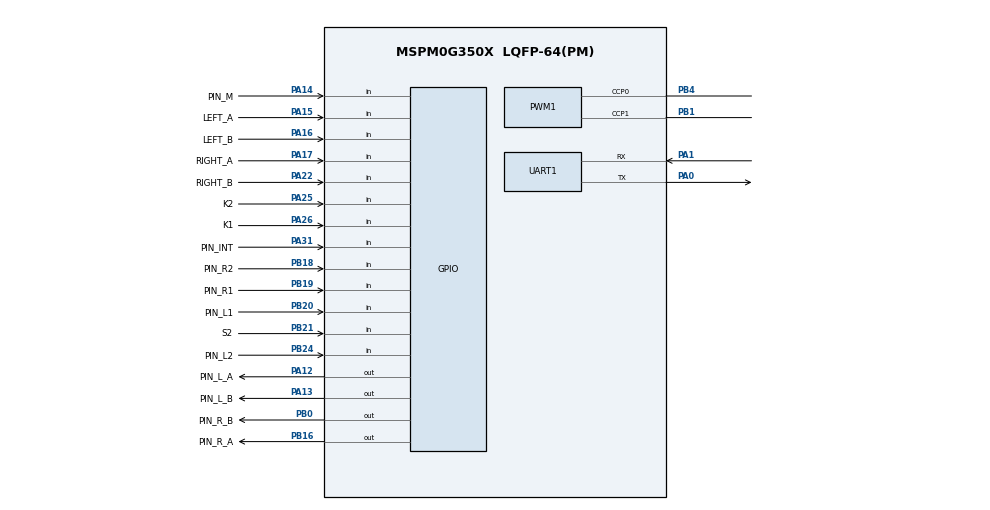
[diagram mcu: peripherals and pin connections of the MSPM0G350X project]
/**
 * @cliArgs --device "MSPM0G350X" --part "Default" --package "LQFP-64(PM)" --product "mspm0_sdk@2.05.01.00"
 * @versions {"tool":"1.24.0+4110"}
 */

/**
 * Import the modules used in this configuration.
 */
const GPIO   = scripting.addModule("/ti/driverlib/GPIO", {}, false);
const GPIO1  = GPIO.addInstance();
const GPIO2  = GPIO.addInstance();
const GPIO3  = GPIO.addInstance();
const GPIO4  = GPIO.addInstance();
const GPIO5  = GPIO.addInstance();
const GPIO6  = GPIO.addInstance();
const PWM    = scripting.addModule("/ti/driverlib/PWM", {}, false);
const PWM1   = PWM.addInstance();
const SYSCTL = scripting.addModule("/ti/driverlib/SYSCTL");
const TIMER  = scripting.addModule("/ti/driverlib/TIMER", {}, false);
const TIMER1 = TIMER.addInstance();
const UART   = scripting.addModule("/ti/driverlib/UART", {}, false);
const UART1  = UART.addInstance();

/**
 * Write custom configuration values to the imported modules.
 */
const divider7       = system.clockTree["PLL_PDIV"];
divider7.divideValue = 2;

const divider9       = system.clockTree["UDIV"];
divider9.divideValue = 2;

const multiplier2         = system.clockTree["PLL_QDIV"];
multiplier2.multiplyValue = 5;

const mux8       = system.clockTree["HSCLKMUX"];
mux8.inputSelect = "HSCLKMUX_SYSPLL2X";

GPIO1.$name                              = "GPIO_MPU6050";
GPIO1.associatedPins[0].$name            = "PIN_INT";
GPIO1.associatedPins[0].direction        = "INPUT";
GPIO1.associatedPins[0].internalResistor = "PULL_UP";
GPIO1.associatedPins[0].interruptEn      = true;
GPIO1.associatedPins[0].polarity         = "FALL";
GPIO1.associatedPins[0].pin.$assign      = "PA31";

const Board = scripting.addModule("/ti/driverlib/Board", {}, false);

GPIO2.$name                         = "GPIO_R";
GPIO2.associatedPins.create(2);
GPIO2.associatedPins[0].$name       = "PIN_R_A";
GPIO2.associatedPins[0].pin.$assign = "PB16";
GPIO2.associatedPins[1].$name       = "PIN_R_B";
GPIO2.associatedPins[1].pin.$assign = "PB0";

GPIO3.$name                         = "GPIO_L";
GPIO3.associatedPins.create(2);
GPIO3.associatedPins[0].$name       = "PIN_L_B";
GPIO3.associatedPins[0].pin.$assign = "PA13";
GPIO3.associatedPins[1].$name       = "PIN_L_A";
GPIO3.associatedPins[1].pin.$assign = "PA12";

GPIO4.$name                         = "GPIO_ECONDER";
GPIO4.associatedPins.create(4);
GPIO4.associatedPins[0].$name       = "LEFT_A";
GPIO4.associatedPins[0].direction   = "INPUT";
GPIO4.associatedPins[0].interruptEn = true;
GPIO4.associatedPins[0].polarity    = "RISE";
GPIO4.associatedPins[0].pin.$assign = "PA15";
GPIO4.associatedPins[1].$name       = "LEFT_B";
GPIO4.associatedPins[1].direction   = "INPUT";
GPIO4.associatedPins[1].pin.$assign = "PA16";
GPIO4.associatedPins[2].direction   = "INPUT";
GPIO4.associatedPins[2].$name       = "RIGHT_A";
GPIO4.associatedPins[2].interruptEn = true;
GPIO4.associatedPins[2].polarity    = "RISE";
GPIO4.associatedPins[2].pin.$assign = "PA17";
GPIO4.associatedPins[3].direction   = "INPUT";
GPIO4.associatedPins[3].$name       = "RIGHT_B";
GPIO4.associatedPins[3].polarity    = "RISE";
GPIO4.associatedPins[3].pin.$assign = "PA22";

GPIO5.$name                         = "GPIO_HUIDU";
GPIO5.associatedPins.create(5);
GPIO5.associatedPins[0].$name       = "PIN_L2";
GPIO5.associatedPins[0].direction   = "INPUT";
GPIO5.associatedPins[0].pin.$assign = "PB24";
GPIO5.associatedPins[1].$name       = "PIN_L1";
GPIO5.associatedPins[1].direction   = "INPUT";
GPIO5.associatedPins[1].pin.$assign = "PB20";
GPIO5.associatedPins[2].$name       = "PIN_M";
GPIO5.associatedPins[2].direction   = "INPUT";
GPIO5.associatedPins[2].pin.$assign = "PA14";
GPIO5.associatedPins[3].$name       = "PIN_R2";
GPIO5.associatedPins[3].direction   = "INPUT";
GPIO5.associatedPins[3].pin.$assign = "PB18";
GPIO5.associatedPins[4].$name       = "PIN_R1";
GPIO5.associatedPins[4].direction   = "INPUT";
GPIO5.associatedPins[4].pin.$assign = "PB19";

GPIO6.$name                              = "KEY";
GPIO6.associatedPins.create(3);
GPIO6.associatedPins[0].$name            = "S2";
GPIO6.associatedPins[0].direction        = "INPUT";
GPIO6.associatedPins[0].pin.$assign      = "PB21";
GPIO6.associatedPins[1].direction        = "INPUT";
GPIO6.associatedPins[1].$name            = "K1";
GPIO6.associatedPins[1].internalResistor = "PULL_UP";
GPIO6.associatedPins[1].pin.$assign      = "PA26";
GPIO6.associatedPins[2].$name            = "K2";
GPIO6.associatedPins[2].direction        = "INPUT";
GPIO6.associatedPins[2].internalResistor = "PULL_UP";
GPIO6.associatedPins[2].pin.$assign      = "PA25";

PWM1.$name                              = "PWM";
PWM1.pwmMode                            = "EDGE_ALIGN_UP";
PWM1.timerCount                         = 200;
PWM1.peripheral.$assign                 = "TIMA1";
PWM1.peripheral.ccp0Pin.$assign         = "PB4";
PWM1.peripheral.ccp1Pin.$assign         = "PB1";
PWM1.PWM_CHANNEL_0.$name                = "ti_driverlib_pwm_PWMTimerCC0";
PWM1.PWM_CHANNEL_1.$name                = "ti_driverlib_pwm_PWMTimerCC1";
PWM1.ccp0PinConfig.direction            = scripting.forceWrite("OUTPUT");
PWM1.ccp0PinConfig.hideOutputInversion  = scripting.forceWrite(false);
PWM1.ccp0PinConfig.onlyInternalResistor = scripting.forceWrite(false);
PWM1.ccp0PinConfig.passedPeripheralType = scripting.forceWrite("Digital");
PWM1.ccp0PinConfig.$name                = "ti_driverlib_gpio_GPIOPinGeneric2";
PWM1.ccp1PinConfig.direction            = scripting.forceWrite("OUTPUT");
PWM1.ccp1PinConfig.hideOutputInversion  = scripting.forceWrite(false);
PWM1.ccp1PinConfig.onlyInternalResistor = scripting.forceWrite(false);
PWM1.ccp1PinConfig.passedPeripheralType = scripting.forceWrite("Digital");
PWM1.ccp1PinConfig.$name                = "ti_driverlib_gpio_GPIOPinGeneric3";

SYSCTL.forceDefaultClkConfig = true;
SYSCTL.clockTreeEn           = true;
scripting.suppress("For best practices when the CPUCLK is running at 32MHz and above, clear the flash status bit using DL_FlashCTL_executeClearStatus\\(\\) before executing any flash operation\\. Otherwise there may be false positives\\.", SYSCTL);

TIMER1.$name              = "TIMER_COUNT";
TIMER1.timerClkPrescale   = 256;
TIMER1.timerMode          = "PERIODIC_UP";
TIMER1.timerPeriod        = "1 ms";
TIMER1.interrupts         = ["ZERO"];
TIMER1.peripheral.$assign = "TIMA0";

UART1.$name                            = "UART_OPENMV";
UART1.enabledInterrupts                = ["RX"];
UART1.peripheral.$assign               = "UART0";
UART1.peripheral.rxPin.$assign         = "PA1";
UART1.peripheral.txPin.$assign         = "PA0";
UART1.txPinConfig.direction            = scripting.forceWrite("OUTPUT");
UART1.txPinConfig.hideOutputInversion  = scripting.forceWrite(false);
UART1.txPinConfig.onlyInternalResistor = scripting.forceWrite(false);
UART1.txPinConfig.passedPeripheralType = scripting.forceWrite("Digital");
UART1.txPinConfig.$name                = "ti_driverlib_gpio_GPIOPinGeneric4";
UART1.rxPinConfig.hideOutputInversion  = scripting.forceWrite(false);
UART1.rxPinConfig.onlyInternalResistor = scripting.forceWrite(false);
UART1.rxPinConfig.passedPeripheralType = scripting.forceWrite("Digital");
UART1.rxPinConfig.$name                = "ti_driverlib_gpio_GPIOPinGeneric5";

/**
 * Pinmux solution for unlocked pins/peripherals. This ensures that minor changes to the automatic solver in a future
 * version of the tool will not impact the pinmux you originally saw.  These lines can be completely deleted in order to
 * re-solve from scratch.
 */
Board.peripheral.$suggestSolution          = "DEBUGSS";
Board.peripheral.swclkPin.$suggestSolution = "PA20";
Board.peripheral.swdioPin.$suggestSolution = "PA19";
